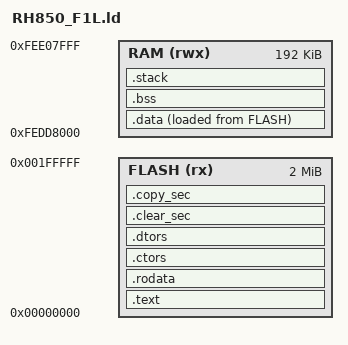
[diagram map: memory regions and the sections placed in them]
/******************************************************************************************
  Filename    : RH850_F1L.ld

  Core        : RH850G3K (v850e3v5)

  Mcu         : R7F701030xAFP (RH850/F1L)

  Author      : Chalandi Amine

  Owner       : Chalandi Amine

  Date        : 02.11.2026

  Description : Linker description file

******************************************************************************************/

/******************************************************************************************
 ELF Entrypoint
******************************************************************************************/
ENTRY(_start)

/******************************************************************************************
 Globals
******************************************************************************************/
__STACK_SIZE = 1K;

/******************************************************************************************
 Memory configuration
******************************************************************************************/

MEMORY
{
  FLASH(rx)     : ORIGIN = 0x00000000, LENGTH = 2M
  RAM(rwx)      : ORIGIN = 0xFEDD8000, LENGTH = 192K
}

/******************************************************************************************
 Sections definition
******************************************************************************************/
SECTIONS
{
  /* Program code (text) */
  .text : ALIGN(4)
  {
    PROVIDE(__CODE_BASE_ADDRESS = .);
    *(.exceptvect)
    *(.intvect)
    *(.boot)
    *(.text)
    . = ALIGN(4);
  } > FLASH

  /* Read-only data (.rodata) */
  .rodata : ALIGN(4)
  {
    PROVIDE(__RODATA_BASE_ADDRESS = .);
    *(.rodata)
  } > FLASH

 /* Section for constructors */
  .ctors : ALIGN(4)
  {
    PROVIDE(__CTOR_LIST__  = .);
    KEEP (*(SORT(.ctors.*)))
    KEEP (*(.ctors))
    KEEP (*(SORT(.init_array.*)))
    KEEP (*(.init_array))
    LONG(-1) ;
    PROVIDE(__CTOR_END__  = .);
    . = ALIGN(4);
  }  > FLASH


  /* Section for destructors */
  .dtors : ALIGN(4)
  {
    PROVIDE(__DTOR_LIST__  = .);
    KEEP (*(SORT(.dtors.*)))
    KEEP (*(.dtors))
    KEEP (*(SORT(.fini_array.*)))
    KEEP (*(.fini_array))
    LONG(-1) ;
    PROVIDE(__DTOR_END__  = .);
    . = ALIGN(4);
  } > FLASH

  /* Runtime clear table */
  .clear_sec : ALIGN(4)
  {
    PROVIDE(__RUNTIME_CLEAR_TABLE = .) ;
    LONG(0 + ADDR(.bss));   LONG(SIZEOF(.bss));
    LONG(-1);                 LONG(-1);
    . = ALIGN(4);
  } > FLASH

  /* Runtime copy table */
  .copy_sec : ALIGN(4)
  {
    PROVIDE(__RUNTIME_COPY_TABLE = .) ;
    LONG(LOADADDR(.data));   LONG(0 + ADDR(.data));   LONG(SIZEOF(.data));
    LONG(-1);                LONG(-1);                LONG(-1);
    . = ALIGN(4);
    PROVIDE(__CODE_END_ADDRESS = .);
  } > FLASH 

  /* The ROM-to-RAM initialized data sections */
  .data : ALIGN(4) 
  {
    *(.data)
    *(.data*)
    . = ALIGN(4);
  } > RAM  AT>FLASH
  
  /* The uninitialized (zero-cleared) data sections */
  .bss : ALIGN(4)
  {
    *(.bss)
    *(.bss*)
    . = ALIGN(4);
  } > RAM

  /* stack definition */
  .stack :
  {
    PROVIDE(__STACK_BOTTOM = .) ;
    . = ALIGN(MAX(__STACK_SIZE , .), 8);
    PROVIDE(__STACK_TOP = .) ;
  } > RAM

}
